# RN821X_RN721X_SOC_V2 register map
File version: v1.0.7
CPU: CM0 r0p0, little endian, no MPU, no FPU, 3 interrupt priority bits
Registers are 32-bit, read-write, reset 0x0 unless marked. A register's access mark holds for its fields unless they carry their own. Offsets are from the block's base; [hi:lo] are bit positions; {n}, {i} and the like mark numbered series; 'fields as' and 'values as' point back to an identical list.

## ISO7816 — ISO7816 interface
Base 0x40038000
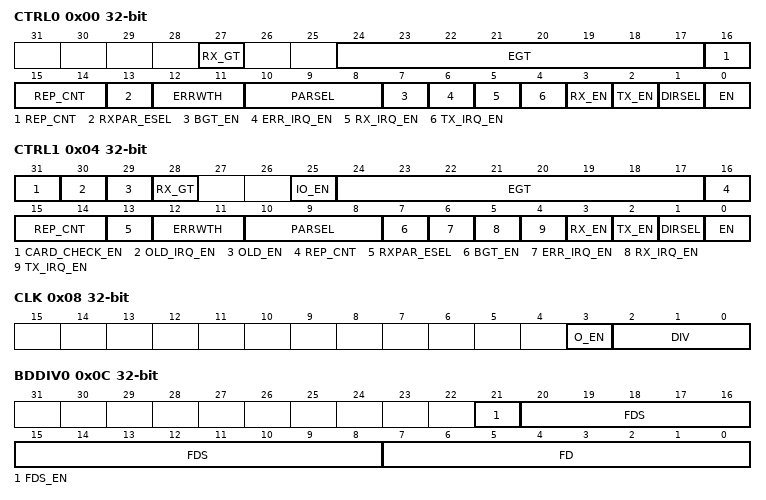
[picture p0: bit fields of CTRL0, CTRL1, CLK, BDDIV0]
0x00 CTRL0 — ISO7816 No.0 control register
  [27] RX_GT — receive data GT selaction bit
    0=2ETU (select receive data GT as 2etu); 1=1ETU (select receive data GT as 1etu)
  [24:17] EGT — EGT width configuration bits
  [16:14] REP_CNT — data parity error resend times selection bits
    0=do not resend when receive parity error; 1=resend 1 time when receive parity error; {v}=resend {v} times when receive parity error (v=2..7)
  [13] RXPAR_ESEL — handling way selection (when receive parity error) bit
    0=NULS (when parity error, set RX_PAR_ERR flag but do not return error signal); 1=SEND (when parity error, set RX_PAR_ERR flag and return error signal by T=0 protocol)
  [12:11] ERRWTH — error signal width selection bits (applicable for RXPAR_ESEL=1 when receive)
    0=2ETU (select 2 etu as error signal width); 1=1ETU (select 1 etu as error signal width); 2=1P5ETU (select 1.5 etu as error signal width)
  [10:8] PARSEL — parity selections
    0=NUL (no parity); 1=ODD (odd parity); 2=EVEN (even parity); 3=ZERO (static zero parity); 4=ONE (static one parity); 5=USER (user defined parity)
  [7] BGT_EN — BGT enable bit
  [6] ERR_IRQ_EN — transfer error interrupt enable bit
  [5] RX_IRQ_EN — receive interrupt enable bit
  [4] TX_IRQ_EN — transmit interrupt enable bit
  [3] RX_EN — receive enable bit
  [2] TX_EN — transmit enable bit
  [1] DIRSEL — data encode and transfer direction selection bit
    0=LSB (data transfered with LSB first); 1=MSB (data toggled and transfered with MSB first)
  [0] EN — ISO7816 controller enable bit
0x04 CTRL1 — ISO7816 No.1 control register
  [31] CARD_CHECK_EN — card draw detection enable.only when CARD_CHECK_EN and OLD_IRQ_EN enable at the same time ,CARD_OUT interrupt enable.
  [30] OLD_IRQ_EN — OLD detection interrupt enable
  [29] OLD_EN — OLD detection enable
  [28] RX_GT — receive GT width
    values as CTRL0.RX_GT
  [25] IO_EN — input output enable
    0=1D (select as output only); 1=2D (select as bidirectional)
  [24:17] EGT — EGT width selection (in etu)
  [16:14] REP_CNT — retry times when parity error found
    values as CTRL0.REP_CNT
  [13] RXPAR_ESEL — receive parity error handling selection
    values as CTRL0.RXPAR_ESEL
  [12:11] ERRWTH — error signal width selection.applicable for RXPAR_ESEL=1 when receive
    values as CTRL0.ERRWTH
  [10:8] PARSEL — parity selection
    values as CTRL0.PARSEL
  [7] BGT_EN — BGT enable
  [6] ERR_IRQ_EN — transfer error interrupt enable
  [5] RX_IRQ_EN — receive interrupt enable
  [4] TX_IRQ_EN — transmit interrupt enable
  [3] RX_EN — receive enable
  [2] TX_EN — transmit enable
  [1] DIRSEL — data encode and transfer direction selection
    values as CTRL0.DIRSEL
  [0] EN — controller enable
0x08 CLK — ISO7816 clock control register
  [3] O_EN — card clock output enable bit
  [2:0] DIV — ISO7816 clock divisor selections bits
    0=NUL (select system clock as iso7816 module clock); 1=select system clock devided by 2 as iso7816 module clock; 2=select system clock devided by 4 as iso7816 module clock; 3=select system clock devided by 8 as iso7816 module clock; 4=select system clock devided by 16 as iso7816 module clock; 5=select system clock devided by 32 as iso7816 module clock; 6=select system clock devided by 64 as iso7816 module clock; 7=select system clock devided by 128 as iso7816 module clock
0x0C BDDIV0 — ISO7816 baudrate coefficients No.0 register
  [21] FDS_EN — F/D config enable
    0=FD (select reset input baud divisor (FD)); 1=FDS (enable soft baud divisor (FDS))
  [20:8] FDS — baudrate coefficient.Only writtalbe when FSD0_EN=1.otherwise read as 372
  [7:0] FD — FI and DI of reset ACK response
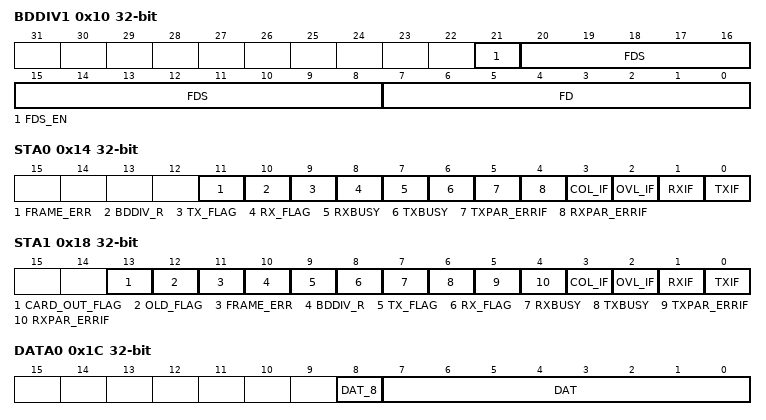
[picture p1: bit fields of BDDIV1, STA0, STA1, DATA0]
0x10 BDDIV1 — ISO7816 baudrate coefficients No.1 register
  fields as BDDIV0
0x14 STA0 — ISO7816 No.0 status register
  [11] FRAME_ERR write-1-clears — receive data frame format error interrupt flag
  [10] BDDIV_R ro — baud matching flag
  [9] TX_FLAG ro — transmit fifo empty flag
  [8] RX_FLAG ro — receive fifo full flag
  [7] RXBUSY ro — receive busy flag
  [6] TXBUSY ro — transmit busy flag
  [5] TXPAR_ERRIF write-1-clears — transmit parity error flag
  [4] RXPAR_ERRIF write-1-clears — receive parity error flag
  [3] COL_IF write-1-clears — transmit conflict error flag
  [2] OVL_IF write-1-clears — receive overflow flag
  [1] RXIF write-1-clears — receive interrupt flag
  [0] TXIF write-1-clears — transmit interrupt flag
0x18 STA1 — ISO7816 NO.1 status register
  [13] CARD_OUT_FLAG write-1-clears — card pull off flag
  [12] OLD_FLAG write-1-clears — OLD signal received flag
  [11] FRAME_ERR write-1-clears — receive data frame format error interrupt flag
  [10] BDDIV_R ro — baud matching flag
  [9] TX_FLAG ro — transmit fifo empty flag
  [8] RX_FLAG ro — receive fifo full flag
  [7] RXBUSY ro — receive busy flag
  [6] TXBUSY ro — transmit busy flag
  [5] TXPAR_ERRIF ro write-1-clears — transmit parity error flag
  [4] RXPAR_ERRIF write-1-clears — receive parity error flag
  [3] COL_IF write-1-clears — transmit conflict error flag
  [2] OVL_IF write-1-clears — receive overflow flag
  [1] RXIF write-1-clears — receive interrupt flag
  [0] TXIF write-1-clears — transmit interrupt flag
0x1C DATA0 — ISO7816 No.0 data register
  [8] DAT_8 — parity bit value(effactive when PARSEL select define by users)
  [7:0] DAT — data bits
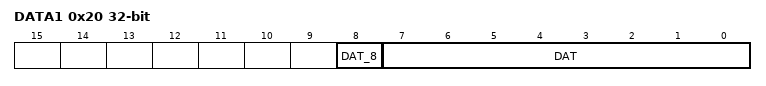
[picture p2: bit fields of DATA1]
0x20 DATA1 — ISO7816 No.1 data register
  fields as DATA0
